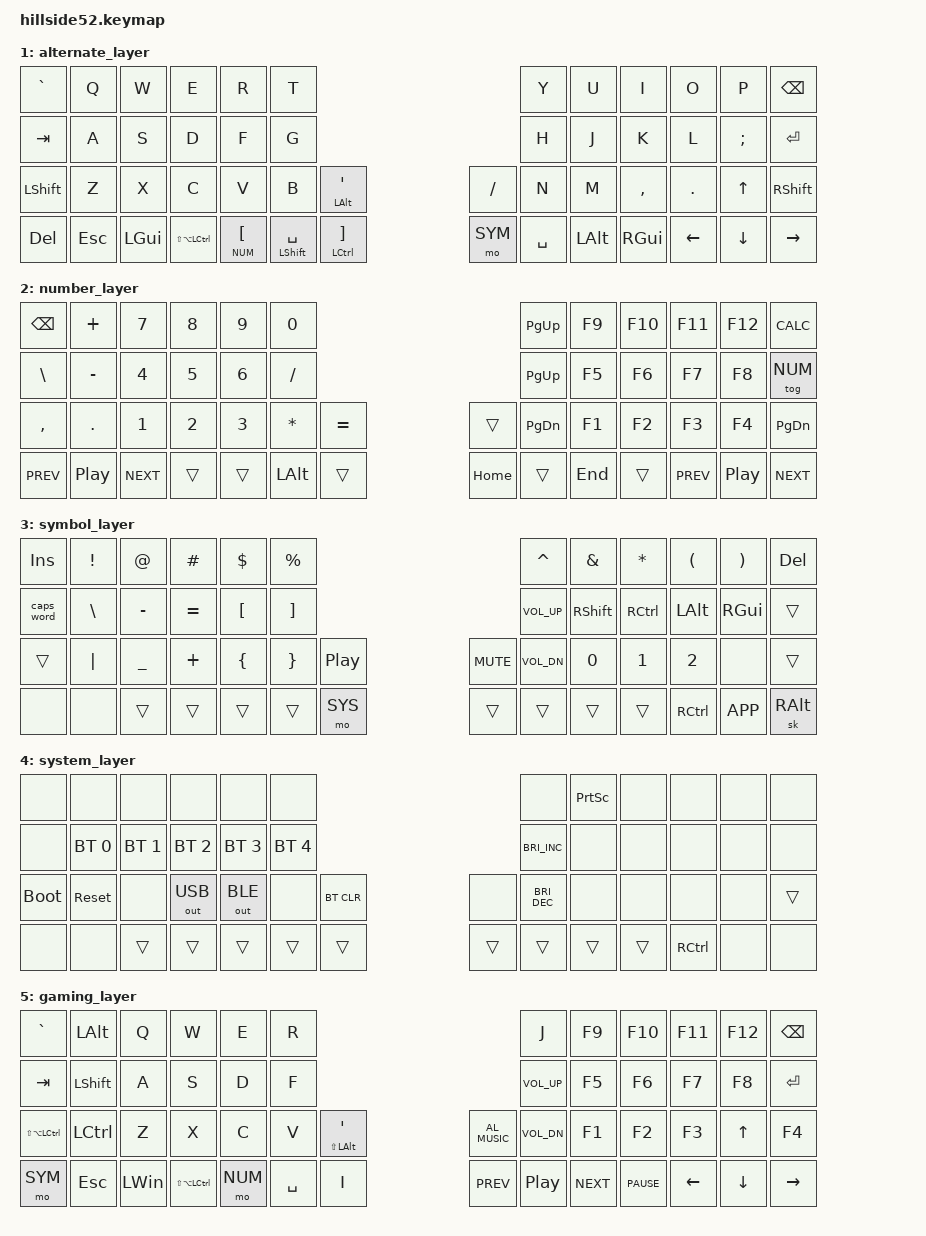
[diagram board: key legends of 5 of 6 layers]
#include <behaviors.dtsi>
#include <dt-bindings/zmk/keys.h>
#include <dt-bindings/zmk/bt.h>
#include <dt-bindings/zmk/outputs.h>
// #include <dt-bindings/zmk/ext_power.h>

#include <zmk-helpers/helper.h>
#include <zmk-helpers/key-labels/hillside52.h>

#define ___ &trans
// transparent key alias
#define xxx &none
// disabled key alias

/* Global Settings */
#define QUICK_TAP_MS 175

&sk {  // sticky-key config
    release-after-ms = <900>;  
    quick-release;             // no double capitalization when rolling keys
};

&sl {  // sticky-layer config
    ignore-modifiers;          // allow chording sticky mods & layers
};

&lt {  // layer-tap config
    flavor = "balanced";
    tapping-term-ms = <200>;
    quick-tap-ms = <175>;
};

&mt {
    flavor = "hold-preferred";
    tapping-term-ms = <150>;
    require-prior-idle-ms = <125>;
};


/* Behaviors
ZMK_HOLD_TAP(hwu,
    tapping-term-ms = <200>;
    #binding-cells = <2>
    require-prior-idle-ms = <125>;
    hold-while-undecided
    bindings = <&kp>, <&kp>;
) */

/* Timeless homerow mods */
// https://github.com/urob/zmk-config/tree/main#timeless-homerow-mods

#define KEYS_L LT0 LT1 LT2 LT3 LT4 LM0 LM1 LM2 LM3 LM4 LB0 LB1 LB2 LB3 LB4  // left hand
#define KEYS_R RT0 RT1 RT2 RT3 RT4 RM0 RM1 RM2 RM3 RM4 RB0 RB1 RB2 RB3 RB4  // right hand
#define THUMBS LH2 LH1 LH0 RH0 RH1 RH2                                  // thumbs on 36+ keys


#define MAKE_HRM(NAME, HOLD, TAP, TRIGGER_POS) \
    ZMK_HOLD_TAP(NAME, \
        flavor = "balanced"; \
        tapping-term-ms = <280>; \
        quick-tap-ms = <QUICK_TAP_MS>; \
        require-prior-idle-ms = <150>; \
        bindings = <HOLD>, <TAP>; \
        hold-trigger-key-positions = <TRIGGER_POS>; \
        hold-trigger-on-release; \
    )
MAKE_HRM(hml, &kp, &kp, KEYS_R THUMBS)  // left-hand HRMs
MAKE_HRM(hmr, &kp, &kp, KEYS_L THUMBS)  // right-hand HRMs

// HRM combo hack - workaround for lack of tap-only combos (ZMK issue #544)
#define ZMK_COMBO_8(NAME, TAP, KEYPOS, LAYERS, COMBO_TERM, COMBO_IDLE, HOLD, SIDE) \
    MAKE_HRM(hm_combo_ ## NAME, &kp, TAP, SIDE THUMBS) \
    ZMK_COMBO_6(NAME, &hm_combo_ ## NAME HOLD 0, KEYPOS, LAYERS, COMBO_TERM, COMBO_IDLE)

/* Nordic unicode characters and their capitals */
ZMK_UNICODE_PAIR(no_aa,   N0, N0, E,  N1,   N0, N0, C,  N1) //  á
ZMK_UNICODE_PAIR(no_ea,   N0, N0, E,  N9,   N0, N0, C,  N9) //  é
ZMK_UNICODE_PAIR(no_ia,   N0, N0, E,  D,    N0, N0, C,  D)  //  í
ZMK_UNICODE_PAIR(no_oa,   N0, N0, F,  N3,   N0, N0, D,  N3) //  ó 
ZMK_UNICODE_PAIR(no_ua,   N0, N0, F,  A,    N0, N0, D,  A)  //  ú
ZMK_UNICODE_PAIR(no_ya,   N0, N0, F,  D,    N0, N0, D,  D)  //  ý
ZMK_UNICODE_PAIR(no_ae,   N0, N0, E,  N6,   N0, N0, C,  N6) //  æ
ZMK_UNICODE_PAIR(no_od,   N0, N0, F,  N6,   N0, N0, D,  N6) //  ö
ZMK_UNICODE_PAIR(no_ad,   N0, N0, E,  N4,   N0, N0, C,  N4) //  ä
ZMK_UNICODE_PAIR(no_thorn,  N0, N0, F,  E,  N0, N0, D,  E)  //  þ 
ZMK_UNICODE_PAIR(no_eth,  N0, N0, F,  N0,   N0, N0, D,  N0) //  ð
ZMK_UNICODE_PAIR(no_ao,   N0, N0, E,  N5,   N0, N0, C,  N5) //  å

/* Other special characters */
ZMK_UNICODE_SINGLE(curr_euro, N2, N0, A, C)  // €
ZMK_UNICODE_SINGLE(sym_section, N0, N0, A, 7)  // §
ZMK_UNICODE_SINGLE(sym_emdash, N2, N0, N1, N4)  // —

// #include "combos.dtsi"
// #include "mouse.dtsi"

/* Hotkey Aliases */
#define DSK_R &kp LG(LC(RIGHT))
#define DSK_L &kp LG(LC(LEFT))
#define MIN_MAX &kp LG(D)
#define FILES &kp LG(E)
#define MEH &kp LC(LA(LSHFT))
#define RMEH &kp RC(RA(RSHFT))
#define HYPER &kp LG(LC(LA(LSHFT)))
#define RHYPER &kp RG(RC(RA(RSHFT)))
#define KILL &kp LA(F4)
#define CYCLE_APPS &kp (LC(LA(TAB)))
#define TASK_VIEW &kp LG(TAB)
#define WAKE &kp LG(LC(LS(B)))
#define LOCK &kp LG(L)
//#define COPILOT &kp F23

#define DEF 0
//colemak_dh layer for me
#define ALT 1
//alternate alpha layer, qwerty for me
#define NUM 2
// number layer including calc functions - should be fully left-hand operable
#define SYM 3
// symbol layer. top row should emulate standard keyboard symbols 
#define SYS 4
// system/adjustment layer. bluetooth profiles, sound, brightness, etc.
#define WIN 5
// a deeper gui layer for windows or powertoys commands
#define GAMING 6
// gaming layer, removing or altering many smart functions/combos for reliable inputs
#define MOUSE 7
// mouse layer

/* Hillside 52 layout */

ZMK_LAYER(default_layer,
    &lt WIN GRAVE       &kp Q                   &kp W           &kp F               &kp P               &kp B                                                                                   &kp J       &kp L       &kp U       &kp Y       &kp SEMI    &kp BSPC
    &mt LG(TAB) TAB     &hml LGUI A             &hml LALT R     &hml LSHFT S        &hml LCTRL T        &kp G                                                                                   &kp M       &kp N       &kp E       &kp I       &kp O       &kp ENTER
    &kp BACKSPACE       &kp Z                   &kp X           &kp C               &kp D               &kp V               &mt LALT APOSTROPHE                                     &kp SLASH   &kp K       &kp H       &kp COMMA   &kp PERIOD  &kp UP      &kp RSHFT
    &kp DELETE          &mt TASK_VIEW ESCAPE    &kp LGUI                            &kp LC(LA(LSHFT))   &lt NUM LBKT        &mt LSHFT SPACE         &mt LCTRL RBKT      &mo SYM     &kp SPACE   &kp LALT    &kp RGUI                &kp LEFT    &kp DOWN    &kp RIGHT
)

ZMK_LAYER(alternate_layer,
    &kp GRAVE   &kp Q    &kp W          &kp E               &kp R                   &kp T                                                                                                   &kp Y       &kp U     &kp I         &kp O     &kp P     &kp BSPC
    &kp TAB     &kp A    &kp S          &kp D               &kp F                   &kp G                                                                                                   &kp H       &kp J     &kp K         &kp L     &kp SEMI  &kp ENTER
    &kp LSHFT   &kp Z    &kp X          &kp C               &kp V                   &kp B                   &mt LEFT_ALT SQT                                                    &kp SLASH   &kp N       &kp M     &kp COMMA     &kp DOT   &kp UP    &kp RSHFT
    &kp DELETE  &kp ESC  &kp LEFT_GUI                       &kp LS(LA(LCTRL))       &lt NUM LEFT_BRACKET    &mt LSHIFT SPACE    &mt LCTRL RIGHT_BRACKET             &mo SYM     &kp SPACE   &kp LALT    &kp RGUI                &kp LEFT  &kp DOWN  &kp RIGHT
)

ZMK_LAYER(number_layer,
    &kp BACKSPACE  &kp PLUS          &kp N7         &kp N8  &kp N9      &kp N0                                                                          &kp PG_UP   &kp F9      &kp F10     &kp F11     &kp F12           &kp K_CALC
    &kp BACKSLASH  &kp MINUS         &kp N4         &kp N5  &kp N6      &kp SLASH                                                                       &kp PG_UP   &kp F5      &kp F6      &kp F7      &kp F8            &tog NUM
    &kp COMMA      &kp PERIOD        &kp N1         &kp N2  &kp N3      &kp ASTRK       &kp EQUAL                                           &trans      &kp PG_DN   &kp F1      &kp F2      &kp F3      &kp F4            &kp PG_DN
    &kp C_PREV     &kp C_PLAY_PAUSE  &kp C_NEXT             &trans      &trans          &kp LEFT_ALT    &trans                  &kp HOME    &trans      &kp END     &trans                  &kp C_PREV  &kp C_PLAY_PAUSE  &kp C_NEXT
)

ZMK_LAYER(symbol_layer,
    &kp INS     &kp EXCL  &kp AT        &kp HASH    &kp DOLLAR      &kp PERCENT                                                             &kp CARET       &kp AMPS        &kp ASTRK   &kp LPAR   &kp RPAR   &kp DEL
    &caps_word  &kp BSLH  &kp MINUS     &kp EQUAL   &kp LBKT        &kp RBKT                                                                &kp C_VOL_UP    &kp RSHFT       &kp RCTRL   &kp LALT   &kp RGUI   &trans
    &trans      &kp PIPE  &kp UNDER     &kp PLUS    &kp LBRC        &kp RBRC    &kp C_PP                                        &kp C_MUTE  &kp C_VOL_DN    &kp N0          &kp N1      &kp N2     &none      &trans
    &none       &none     &trans                    &trans          &trans      &trans      &mo SYS                 &trans      &trans      &trans          &trans                      &kp RCTRL  &kp K_APP  &sk RALT
)

ZMK_LAYER(system_layer,
    &none        &none         &none         &none          &none         &none                                                                     &none                   &kp PRINTSCREEN     &none       &none               &none               &none
    &none        &bt BT_SEL 0  &bt BT_SEL 1  &bt BT_SEL 2   &bt BT_SEL 3  &bt BT_SEL 4                                                              &kp C_BRIGHTNESS_INC    &none               &none       &none               &none               &none
    &bootloader  &sys_reset    &none         &out OUT_USB   &out OUT_BLE  &none         &bt BT_CLR                                          &none   &kp C_BRIGHTNESS_DEC    &none               &none       &none               &none               &trans
    &none        &none         &trans                       &trans        &trans        &trans         &trans                      &trans   &trans  &trans                  &trans                          &kp RCTRL           &none               &none
)

ZMK_LAYER(windows_layer,
    &trans  &kp LA(F4)  &kp LG(D)   &kp LG(E)   &kp LG(LC(LA(LS(LESS_THAN))))   &kp LG(LC(LA(LS(GREATER_THAN))))                                                            &trans  &kp LG(LC(LA(N1)))  &kp LG(LA(N2))      &kp LG(LC(LA(N3)))      &kp LG(LC(LA(N4)))      &kp LG(LC(LS(LA(LEFT))))
    &trans  &trans      &kp LG(N1)  &kp LG(N2)  &kp LG(N3)                      &kp LG(N4)                                                                                  &trans  &kp LG(H)           &kp LG(J)           &kp LG(K)               &kp LG(L)               &kp LG(LC(LS(RIGHT)))
    &trans  &trans      &trans      &trans      &mt LC(F4) LG(LC(D))            &trans              &kp DOUBLE_QUOTES                                               &trans  &trans  &trans              &trans              &trans                  &kp LG(LS(LA(LC(N8))))  &trans
    &trans  &trans      &trans                  &trans                          &kp LG(LC(LEFT))    &kp LA(SPACE)       &kp LC(LG(RIGHT))                   &trans  &trans  &trans  &trans                                  &kp LG(LA(LS(LC(N4))))  &kp LG(LS(LC(LA(N2))))  &kp LG(LA(LS(LC(N6))))
)

ZMK_LAYER(gaming_layer,
    &kp GRAVE           &kp LEFT_ALT    &kp Q           &kp W               &kp E               &kp R                                                                                                               &kp J               &kp F9          &kp F10         &kp F11     &kp F12   &kp BSPC
    &kp TAB             &kp LEFT_SHIFT  &kp A           &kp S               &kp D               &kp F                                                                                                               &kp C_VOL_UP        &kp F5          &kp F6          &kp F7      &kp F8    &kp ENTER
    &kp LS(LA(LCTRL))   &kp LCTRL       &kp Z           &kp X               &kp C               &kp V       &mt LS(LEFT_ALT) APOSTROPHE                                                         &kp C_AL_MUSIC      &kp C_VOL_DN        &kp F1          &kp F2          &kp F3      &kp UP    &kp F4
    &mo SYM             &kp ESC         &kp LEFT_WIN                        &kp LS(LA(LCTRL))   &mo NUM     &kp SPACE                       &kp I                               &kp C_PREV      &kp C_PLAY_PAUSE    &kp C_NEXT      &kp C_PAUSE                         &kp LEFT    &kp DOWN  &kp RIGHT
)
